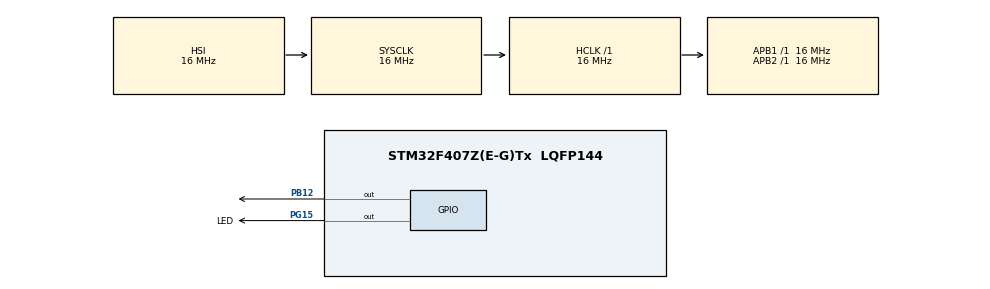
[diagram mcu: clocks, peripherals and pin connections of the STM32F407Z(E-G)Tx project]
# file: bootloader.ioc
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FREERTOS.Tasks01=defaultTask,0,128,StartDefaultTask,Default,NULL
Mcu.Family=STM32F4
Mcu.Name=STM32F407Z(E-G)Tx
Mcu.Package=LQFP144
NVIC.PriorityGroup=NVIC_PRIORITYGROUP_4
PA13.Mode=Serial_Wire
PA13.Signal=SYS_JTMS-SWDIO
PA14.Mode=Serial_Wire
PA14.Signal=SYS_JTCK-SWCLK
PB12.GPIO_ModeDefaultOutputPP=GPIO_MODE_OUTPUT_PP
PB12.PinState=GPIO_PIN_SET
PB12.Signal=GPIO_Output
PG15.GPIO_Label=LED
PG15.Signal=GPIO_Output
ProjectManager.HeapSize=0x200
ProjectManager.StackSize=0x400
ProjectManager.TargetToolchain=TrueSTUDIO
RCC.AHBFreq_Value=16000000
RCC.APB1Freq_Value=16000000
RCC.APB2Freq_Value=16000000
RCC.CortexFreq_Value=16000000
RCC.HSE_VALUE=25000000
RCC.HSI_VALUE=16000000
RCC.LSE_VALUE=32768
RCC.SYSCLKFreq_VALUE=16000000
RCC.VCOOutputFreq_Value=192000000
VP_FREERTOS_VS_CMSIS_V1.Mode=CMSIS_V1
board=custom

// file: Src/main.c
/* USER CODE BEGIN Header */
/**
  ******************************************************************************
  * @file           : main.c
  * @brief          : Main program body
  ******************************************************************************
  * @attention
  *
  * <h2><center>&copy; Copyright (c) 2019 STMicroelectronics.
  * All rights reserved.</center></h2>
  *
  * This software component is licensed by ST under Ultimate Liberty license
  * SLA0044, the "License"; You may not use this file except in compliance with
  * the License. You may obtain a copy of the License at:
  *                             www.st.com/SLA0044
  *
  ******************************************************************************
  */
/* USER CODE END Header */

#include "main.h"
#include "cmsis_os.h"
#include "gpio.h"

void SystemClock_Config(void);
void MX_FREERTOS_Init(void);

int main(void)
{

  /* MCU Configuration--------------------------------------------------------*/

  /* Reset of all peripherals, Initializes the Flash interface and the Systick. */
  HAL_Init();

  /* Configure the system clock */
  SystemClock_Config();

  /* Initialize all configured peripherals */
  MX_GPIO_Init();

  /* Call init function for freertos objects (in freertos.c) */
  MX_FREERTOS_Init();

  /* Start scheduler */
  osKernelStart();

  /* We should never get here as control is now taken by the scheduler */

  /* Infinite loop */
  while (1)
  {

  }
}

void SystemClock_Config(void)
{
  RCC_OscInitTypeDef RCC_OscInitStruct = {0};
  RCC_ClkInitTypeDef RCC_ClkInitStruct = {0};

  /** Configure the main internal regulator output voltage
  */
  __HAL_RCC_PWR_CLK_ENABLE();
  __HAL_PWR_VOLTAGESCALING_CONFIG(PWR_REGULATOR_VOLTAGE_SCALE1);
  /** Initializes the CPU, AHB and APB busses clocks
  */
  RCC_OscInitStruct.OscillatorType = RCC_OSCILLATORTYPE_HSI;
  RCC_OscInitStruct.HSIState = RCC_HSI_ON;
  RCC_OscInitStruct.HSICalibrationValue = RCC_HSICALIBRATION_DEFAULT;
  RCC_OscInitStruct.PLL.PLLState = RCC_PLL_NONE;
  if (HAL_RCC_OscConfig(&RCC_OscInitStruct) != HAL_OK)
  {
    Error_Handler();
  }
  /** Initializes the CPU, AHB and APB busses clocks
  */
  RCC_ClkInitStruct.ClockType = RCC_CLOCKTYPE_HCLK|RCC_CLOCKTYPE_SYSCLK
                              |RCC_CLOCKTYPE_PCLK1|RCC_CLOCKTYPE_PCLK2;
  RCC_ClkInitStruct.SYSCLKSource = RCC_SYSCLKSOURCE_HSI;
  RCC_ClkInitStruct.AHBCLKDivider = RCC_SYSCLK_DIV1;
  RCC_ClkInitStruct.APB1CLKDivider = RCC_HCLK_DIV1;
  RCC_ClkInitStruct.APB2CLKDivider = RCC_HCLK_DIV1;

  if (HAL_RCC_ClockConfig(&RCC_ClkInitStruct, FLASH_LATENCY_0) != HAL_OK)
  {
    Error_Handler();
  }
}

void Error_Handler(void)
{
}

/************************ (C) COPYRIGHT STMicroelectronics *****END OF FILE****/

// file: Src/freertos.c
/* USER CODE BEGIN Header */
/**
  ******************************************************************************
  * File Name          : freertos.c
  * Description        : Code for freertos applications
  ******************************************************************************
  * @attention
  *
  * <h2><center>&copy; Copyright (c) 2019 STMicroelectronics.
  * All rights reserved.</center></h2>
  *
  * This software component is licensed by ST under Ultimate Liberty license
  * SLA0044, the "License"; You may not use this file except in compliance with
  * the License. You may obtain a copy of the License at:
  *                             www.st.com/SLA0044
  *
  ******************************************************************************
  */
/* USER CODE END Header */

#include "FreeRTOS.h"
#include "task.h"
#include "main.h"
#include "cmsis_os.h"

osThreadId defaultTaskHandle;

void StartDefaultTask(void const * argument);

void MX_FREERTOS_Init(void); /* (MISRA C 2004 rule 8.1) */

void MX_FREERTOS_Init(void) {

  /* Create the thread(s) */
  /* definition and creation of defaultTask */
  osThreadDef(defaultTask, StartDefaultTask, osPriorityNormal, 0, 128);
  defaultTaskHandle = osThreadCreate(osThread(defaultTask), NULL);

}

/* USER CODE BEGIN Header_StartDefaultTask */
/**
  * @brief  Function implementing the defaultTask thread.
  * @param  argument: Not used
  * @retval None
  */

uint32_t addr;
typedef  void (*pFunction)(void);
#define Address 0x8020000
/* USER CODE END Header_StartDefaultTask */
void StartDefaultTask(void const * argument)
{

  /* USER CODE BEGIN StartDefaultTask */
  /* Infinite loop */
  for(;;)
  {
	  HAL_GPIO_TogglePin(LED_GPIO_Port, LED_Pin);
    osDelay(1000);
	HAL_GPIO_TogglePin(LED_GPIO_Port, LED_Pin);
	osDelay(1000);
	HAL_GPIO_TogglePin(LED_GPIO_Port, LED_Pin);
	osDelay(1000);
	HAL_GPIO_TogglePin(LED_GPIO_Port, LED_Pin);
	osDelay(1000);

	pFunction Jump_To_Application;
	uint32_t JumpAddress;
//	if( ((*(__IO uint32_t*)APP_START_ADDRESS) & 0x2FFE0000 ) == 0x20000000)
	   {
	    __disable_irq();
	       //跳转至用户代码
	    JumpAddress = *(__IO uint32_t*) (Address + 4);
	    Jump_To_Application = (pFunction) JumpAddress;
	    //初始化用户程序的堆栈指针
	    __set_MSP(*(__IO uint32_t*) Address);
	    NVIC_SetVector(FLASH_IRQn,0x08005000);
	    Jump_To_Application();
	   }

//	void (*pfn)(void);
//	uint32_t *p;
//	pfn = (void (*)(void))(0x08020004);
//	__set_MSP(*(__IO uint32_t*) 0x08020000);
////	p=(uint32_t *)0x08020000;
////	addr = *p;
//	(*pfn)();
  }
  /* USER CODE END StartDefaultTask */
}

/************************ (C) COPYRIGHT STMicroelectronics *****END OF FILE****/
